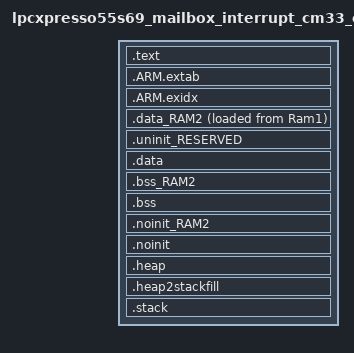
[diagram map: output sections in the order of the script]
/*
 * GENERATED FILE - DO NOT EDIT
 * Copyright 2008-2013 Code Red Technologies Ltd,
 * Copyright 2013-2024 NXP
 * Generated linker script file for LPC55S69
 * Created from linkscript.ldt by FMCreateLinkLibraries
 * Using Freemarker v2.3.30
 * MCUXpresso IDE v11.10.0 [Build 3148] [2024-07-03] on Oct 14, 2024, 6:18:20 PM
 */

INCLUDE "lpcxpresso55s69_mailbox_interrupt_cm33_core1_Debug_library.ld"
INCLUDE "lpcxpresso55s69_mailbox_interrupt_cm33_core1_Debug_memory.ld"

ENTRY(ResetISR)

SECTIONS
{
     /* MAIN TEXT SECTION */
    .text : ALIGN(4)
    {
        FILL(0xff)
        __vectors_start__ = ABSOLUTE(.) ;
        KEEP(*(.isr_vector))
        /* Global Section Table */
        . = ALIGN(4) ;
        __section_table_start = .;
        __data_section_table = .;
        LONG(LOADADDR(.data));
        LONG(    ADDR(.data));
        LONG(  SIZEOF(.data));
        LONG(LOADADDR(.data_RAM2));
        LONG(    ADDR(.data_RAM2));
        LONG(  SIZEOF(.data_RAM2));
        __data_section_table_end = .;
        __bss_section_table = .;
        LONG(    ADDR(.bss));
        LONG(  SIZEOF(.bss));
        LONG(    ADDR(.bss_RAM2));
        LONG(  SIZEOF(.bss_RAM2));
        __bss_section_table_end = .;
        __section_table_end = . ;
        /* End of Global Section Table */

        *(.after_vectors*)

       *(.text*)
       *(.rodata .rodata.* .constdata .constdata.*)
       . = ALIGN(4);
    } > Ram1
    /*
     * for exception handling/unwind - some Newlib functions (in common
     * with C++ and STDC++) use this.
     */
    .ARM.extab : ALIGN(4)
    {
        *(.ARM.extab* .gnu.linkonce.armextab.*)
    } > Ram1

    .ARM.exidx : ALIGN(4)
    {
        __exidx_start = .;
        *(.ARM.exidx* .gnu.linkonce.armexidx.*)
        __exidx_end = .;
    } > Ram1
 
    _etext = .;
        
    /* DATA section for shmem */

    .data_RAM2 : ALIGN(4)
    {
        FILL(0xff)
        PROVIDE(__start_data_RAM2 = .) ;
        PROVIDE(__start_data_shmem = .) ;
        *(.ramfunc.$RAM2)
        *(.ramfunc.$shmem)
        *(.data.$RAM2)
        *(.data.$shmem)
        *(.data.$RAM2.*)
        *(.data.$shmem.*)
        . = ALIGN(4) ;
        PROVIDE(__end_data_RAM2 = .) ;
        PROVIDE(__end_data_shmem = .) ;
     } > shmem AT>Ram1

    /* MAIN DATA SECTION */
    .uninit_RESERVED (NOLOAD) : ALIGN(4)
    {
        _start_uninit_RESERVED = .;
        KEEP(*(.bss.$RESERVED*))
       . = ALIGN(4) ;
        _end_uninit_RESERVED = .;
    } > Ram1 AT> Ram1

    /* Main DATA section (Ram1) */
    .data : ALIGN(4)
    {
       FILL(0xff)
       _data = . ;
       PROVIDE(__start_data_RAM = .) ;
       PROVIDE(__start_data_Ram1 = .) ;
       *(vtable)
       *(.ramfunc*)
       KEEP(*(CodeQuickAccess))
       KEEP(*(DataQuickAccess))
       *(RamFunction)
       *(.data*)
       . = ALIGN(4) ;
       _edata = . ;
       PROVIDE(__end_data_RAM = .) ;
       PROVIDE(__end_data_Ram1 = .) ;
    } > Ram1 AT>Ram1

    /* BSS section for shmem */
    .bss_RAM2 (NOLOAD) : ALIGN(4)
    {
       PROVIDE(__start_bss_RAM2 = .) ;
       PROVIDE(__start_bss_shmem = .) ;
       *(.bss.$RAM2)
       *(.bss.$shmem)
       *(.bss.$RAM2.*)
       *(.bss.$shmem.*)
       . = ALIGN (. != 0 ? 4 : 1) ; /* avoid empty segment */
       PROVIDE(__end_bss_RAM2 = .) ;
       PROVIDE(__end_bss_shmem = .) ;
    } > shmem AT> shmem

    /* MAIN BSS SECTION */
    .bss (NOLOAD) : ALIGN(4)
    {
        _bss = .;
        PROVIDE(__start_bss_RAM = .) ;
        PROVIDE(__start_bss_Ram1 = .) ;
        *(.bss*)
        *(COMMON)
        . = ALIGN(4) ;
        _ebss = .;
        PROVIDE(__end_bss_RAM = .) ;
        PROVIDE(__end_bss_Ram1 = .) ;
        PROVIDE(end = .);
    } > Ram1 AT> Ram1

    /* NOINIT section for shmem */
    .noinit_RAM2 (NOLOAD) : ALIGN(4)
    {
       PROVIDE(__start_noinit_RAM2 = .) ;
       PROVIDE(__start_noinit_shmem = .) ;
       *(.noinit.$RAM2)
       *(.noinit.$shmem)
       *(.noinit.$RAM2.*)
       *(.noinit.$shmem.*)
       . = ALIGN(4) ;
       PROVIDE(__end_noinit_RAM2 = .) ;
       PROVIDE(__end_noinit_shmem = .) ;
    } > shmem AT> shmem

    /* DEFAULT NOINIT SECTION */
    .noinit (NOLOAD): ALIGN(4)
    {
        _noinit = .;
        PROVIDE(__start_noinit_RAM = .) ;
        PROVIDE(__start_noinit_Ram1 = .) ;
        *(.noinit*)
         . = ALIGN(4) ;
        _end_noinit = .;
       PROVIDE(__end_noinit_RAM = .) ;
       PROVIDE(__end_noinit_Ram1 = .) ;        
    } > Ram1 AT> Ram1

    /* Reserve and place Heap within memory map */
    _HeapSize = 0xc00;
    .heap (NOLOAD) :  ALIGN(4)
    {
        _pvHeapStart = .;
        . += _HeapSize;
        . = ALIGN(4);
        _pvHeapLimit = .;
    } > Ram1

     _StackSize = 0xc00;
     /* Reserve space in memory for Stack */
    .heap2stackfill (NOLOAD) :
    {
        . += _StackSize;
    } > Ram1
    /* Locate actual Stack in memory map */
    .stack ORIGIN(Ram1) + LENGTH(Ram1) - _StackSize - 0 (NOLOAD) :  ALIGN(4)
    {
        _vStackBase = .;
        . = ALIGN(4);
        _vStackTop = . + _StackSize;
    } > Ram1

    /* Provide basic symbols giving location and size of main text
     * block, including initial values of RW data sections. Note that
     * these will need extending to give a complete picture with
     * complex images (e.g multiple Flash banks).
     */
    _image_start = LOADADDR(.text);
    _image_end = LOADADDR(.data) + SIZEOF(.data);
    _image_size = _image_end - _image_start;
}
